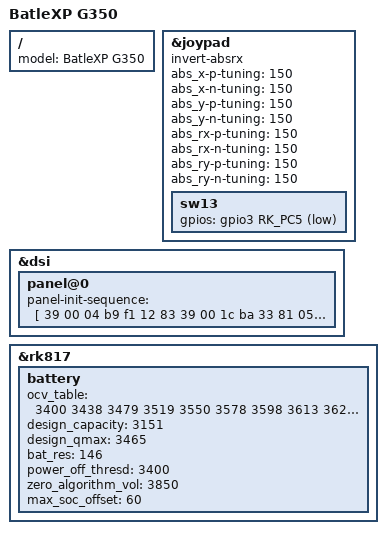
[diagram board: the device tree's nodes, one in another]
// SPDX-License-Identifier: (GPL-2.0+ OR MIT)
/*
 * BatleXP G350: the genuine R36S board with the panel 5 init sequence and its
 * own battery, F5 button pin and right stick. Everything else (CPU, power,
 * USB, sleep, fixes) comes from rk3326-r36s-android.dtsi, like the R46H.
 * Screen, sound and second slot: a G350 owner's working andr36oid DTB
 * (panel 5 without its enable pin; the R36S timing and headphone detect).
 * Battery, F5 pin and right stick from the G350 ArkOS DTB by Christian
 * Haitian, shared by Russ Crandall (github.com/retrogamecorps/G350-ArkOS-dtb).
 * Not tested by andr36oid on the console.
 */

/dts-v1/;
#include "rk3326-r36s-android.dtsi"

/ {
	model = "BatleXP G350";
};

&joypad {
	/* the right stick's X axis runs the other way */
	invert-absrx;
	abs_x-p-tuning = <150>;
	abs_x-n-tuning = <150>;
	abs_y-p-tuning = <150>;
	abs_y-n-tuning = <150>;
	abs_rx-p-tuning = <150>;
	abs_rx-n-tuning = <150>;
	abs_ry-p-tuning = <150>;
	abs_ry-n-tuning = <150>;

	sw13 {
		gpios = <&gpio3 RK_PC5 GPIO_ACTIVE_LOW>;
	};
};

&dsi {
	panel@0 {
		panel-init-sequence = [
			39 00 04 b9 f1 12 83
			39 00 1c ba 33 81 05 f9 0e 0e 20 00 00 00 00 00 00 00 44 25 00 91 0a 00 00 02 4f d1 00 00 37
			15 00 02 b8 25
			39 00 04 bf 02 11 00
			39 00 0b b3 0c 10 0a 50 03 ff 00 00 00 00
			39 00 0a c0 73 73 50 50 00 00 08 70 00
			15 00 02 bc 46
			15 00 02 cc 0b
			15 00 02 b4 80
			39 00 04 b2 00 13 f0
			39 00 0f e3 07 07 0b 0b 03 0b 00 00 00 00 ff 00 c0 10
			39 00 0d c1 53 00 1e 1e 77 e1 cc dd 67 77 33 33
			39 00 03 b5 10 10
			39 00 03 b6 6c 7c
			39 00 40 e9 08 00 0e 00 00 b0 b1 11 31 23 28 10 b0 b1 27 08 00 04 02 00 00 00 00 04 02 00 00 00 88 88 ba 60 24 08 88 88 88 88 88 88 88 ba 71 35 18 88 88 88 88 88 00 00 00 01 00 00 00 00 00 00 00 00 00
			39 00 3e ea 97 0a 82 02 13 07 00 00 00 00 00 00 80 88 ba 17 53 88 88 88 88 88 88 81 88 ba 06 42 88 88 88 88 88 88 23 10 00 02 80 00 00 00 00 00 00 00 00 00 00 00 00 00 00 00 00 00 00 00 00 00 00
			39 00 23 e0 00 07 0b 27 2d 3f 3b 37 05 0a 0b 0f 11 0f 12 12 18 00 07 0b 27 2d 3f 3b 37 05 0a 0b 0f 11 0f 12 12 18
			05 96 01 11
			05 32 01 29
		];
	};
};

&rk817 {
	battery {
		ocv_table = <3400 3438 3479 3519 3550 3578 3598
			3613 3629 3647 3672 3713 3762 3807
			3852 3895 3939 3990 4035 4092 4172>;
		design_capacity = <3151>;
		design_qmax = <3465>;
		bat_res = <146>;
		power_off_thresd = <3400>;
		zero_algorithm_vol = <3850>;
		max_soc_offset = <60>;
	};
};
